# TMS320F280049 register map
Vendor: Texas Instruments; Series: C2000 F28004x; File version: 0.2.0-generated
Registers are 16-bit, read-write, reset 0x0 unless marked. A register's access mark holds for its fields unless they carry their own. Offsets are from the block's base; [hi:lo] are bit positions; {n}, {i} and the like mark numbered series.

## ADCARESULTREGS — ADC RESULT Registers
Base 0x00001600
Same registers: ADCBRESULTREGS 0x00001640, ADCCRESULTREGS 0x00001680
{0x0+2i} ADCRESULT{i} (i=0..15)
  [15] RESULT — ADC Result
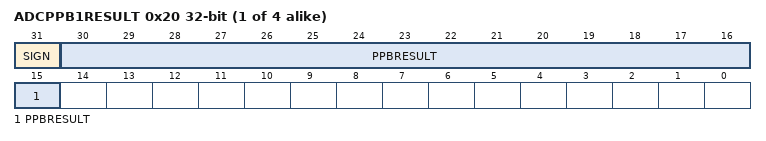
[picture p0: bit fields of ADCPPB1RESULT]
{0x1C+4i} ADCPPB{i}RESULT 32-bit (i=1..4) — ADC Post Processing Block {i} Result Register
  [31] SIGN — Sign Extended Bits
  [30:15] PPBRESULT — ADC Post Processing Block Result

## CLA1ONLYREGS — CLA ONLY Registers
Base 0x00001800
0x100 MVECTBGRNDACTIVE — Active register for MVECTBGRND.
  [15] I16 — Active register for the Background Task Vector
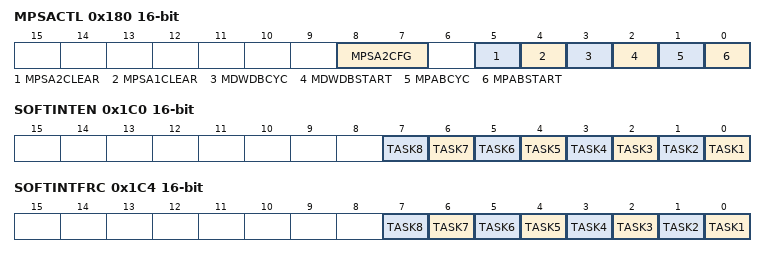
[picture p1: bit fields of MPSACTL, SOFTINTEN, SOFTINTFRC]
0x180 MPSACTL — CLA PSA Control Register
  [8:7] MPSA2CFG — PSA2 Polynomial Configuration
  [5] MPSA2CLEAR — PSA2 Clear
  [4] MPSA1CLEAR — PSA1 clear
  [3] MDWDBCYC — DWDB logging into PSA2 is on every cycle.
  [2] MDWDBSTART — Start logging DWDB onto PSA2
  [1] MPABCYC — PAB logging into PSA1 is on every cycle or when PAB changes.
  [0] MPABSTART — Start logging PAB onto PSA1
0x184 MPSA1 32-bit — CLA PSA1 Register
  [31] I32 — PSA1
0x188 MPSA2 32-bit — CLA PSA2 Register
  [31] I32 — PSA2
0x1C0 SOFTINTEN — CLA Software Interrupt Enable Register
  [n-1] TASK{n} (n=1..8) — Configure Software Interrupt or End of Task interrupt.
0x1C4 SOFTINTFRC — CLA Software Interrupt Force Register
  [n-1] TASK{n} (n=1..8) — Force CLA software interrupt for the corresponding task.

## CPUTIMER0REGS — CPUTIMER Registers
Base 0x00001800
Same registers: CPUTIMER1REGS 0x00001810, CPUTIMER2REGS 0x00001820
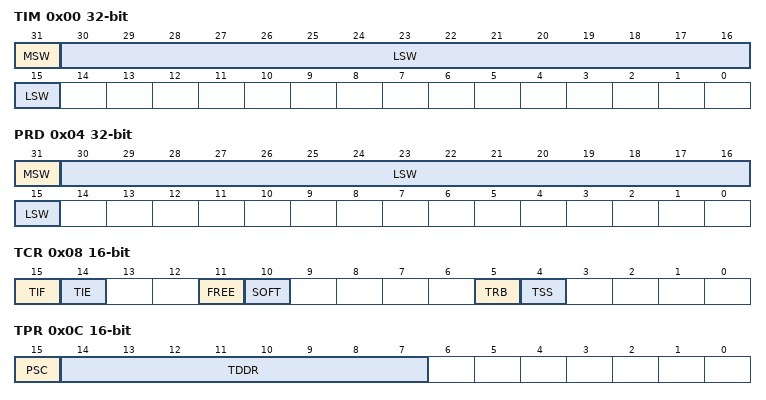
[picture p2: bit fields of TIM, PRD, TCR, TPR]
0x00 TIM 32-bit — CPU-Timer, Counter Register
  [31] MSW — CPU-Timer Counter Registers High
  [30:15] LSW — CPU-Timer Counter Registers
0x04 PRD 32-bit — CPU-Timer, Period Register
  [31] MSW — CPU-Timer Period Registers High
  [30:15] LSW — CPU-Timer Period Registers
0x08 TCR — CPU-Timer, Control Register
  [15] TIF — CPU-Timer Interrupt Flag.
  [14] TIE — CPU-Timer Interrupt Enable.
  [11] FREE — Emulation modes
  [10] SOFT — Emulation modes
  [5] TRB — Timer reload
  [4] TSS — CPU-Timer stop status bit.
0x0C TPR — CPU-Timer, Prescale Register
  [15] PSC — CPU-Timer Prescale Counter.
  [14:7] TDDR — CPU-Timer Divide-Down.
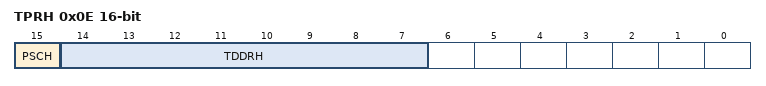
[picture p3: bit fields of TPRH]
0x0E TPRH — CPU-Timer, Prescale Register High
  [15] PSCH — CPU-Timer Prescale Counter.
  [14:7] TDDRH — CPU-Timer Divide-Down.

## FPU — Floating-Point Unit Single Precision Registers
Base 0x00001E00
0x00 RB 32-bit — Repeat Block Register
  [31] RAS — Repeat block shadow active
  [30] RA — Repeat block active
  [31:29] RSIZE — Repeat block size
  [28:22] RE — Repeat block end
  [30:15] RC — Repeat count
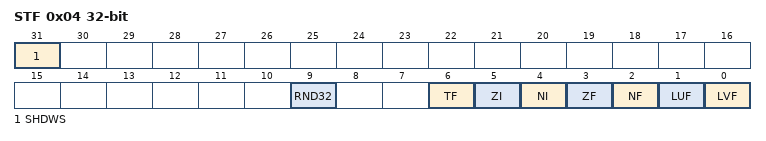
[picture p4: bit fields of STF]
0x04 STF 32-bit — Floating-Point Status Register
  [31] SHDWS — Shadow mode status
  [9] RND32 — Rounding mode
  [6] TF — Test flag
  [5] ZI — Zero integer flag
  [4] NI — Negative integer flag
  [3] ZF — Zero float flag
  [2] NF — Negative flaot flag
  [1] LUF — Latched underflow
  [0] LVF — Latched overflow
{0x24+8i} R{i}H 32-bit (i=0..7)

## DMAREGS — DMA Registers
Base 0x00002000
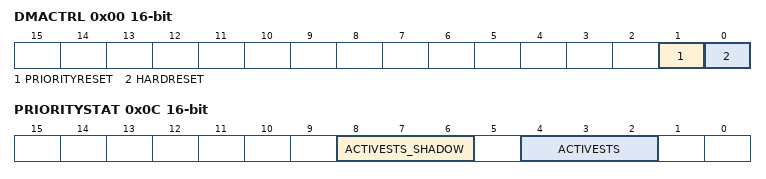
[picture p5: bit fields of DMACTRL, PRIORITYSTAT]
0x00 DMACTRL — DMA Control Register
  [1] PRIORITYRESET — Priority Reset Bit
  [0] HARDRESET — Hard Reset Bit
0x02 DEBUGCTRL — Debug Control Register
  [15] FREE — Debug Mode Bit
0x08 PRIORITYCTRL1 — Priority Control 1 Register
  [0] CH1PRIORITY — Ch1 Priority Bit
0x0C PRIORITYSTAT — Priority Status Register
  [8:6] ACTIVESTS_SHADOW — Active Channel Status Shadow Bits
  [4:2] ACTIVESTS — Active Channel Status Bits

## DMACH1REGS — DMA CH Registers
Base 0x00002040
Same registers: DMACH2REGS 0x00002080, DMACH3REGS 0x000020C0, DMACH4REGS 0x00002100, DMACH5REGS 0x00002140, DMACH6REGS 0x00002180
0x00 MODE
  [15] CHINTE — Channel Interrupt Enable Bit
  [14] DATASIZE — Data Size Mode Bit
  [11] CONTINUOUS — Continuous Mode Bit
  [10] ONESHOT — One Shot Mode Bit
  [9] CHINTMODE — Channel Interrupt Mode
  [8] PERINTE — Peripheral Interrupt Enable
  [7] OVRINTE — Overflow Interrupt Enable
  [8:4] PERINTSEL — Peripheral Interrupt and Sync Select
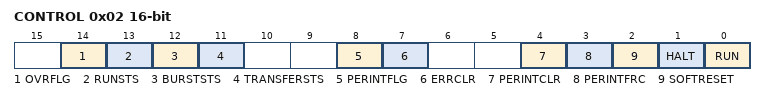
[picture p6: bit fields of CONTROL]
0x02 CONTROL
  [14] OVRFLG — Overflow Flag Bit
  [13] RUNSTS — Run Status Bit
  [12] BURSTSTS — Burst Status Bit
  [11] TRANSFERSTS — Transfer Status Bit
  [8] PERINTFLG — Interrupt Flag Bit
  [7] ERRCLR — Error Clear Bit
  [4] PERINTCLR — Interrupt Clear Bit
  [3] PERINTFRC — Interrupt Force Bit
  [2] SOFTRESET — Soft Reset Bit
  [1] HALT — Halt Bit
  [0] RUN — Run Bit
0x04 BURST_SIZE
  [8:4] BURSTSIZE — Burst Transfer Size
0x06 BURST_COUNT
  [8:4] BURSTCOUNT — Burst Transfer Size
0x08 SRC_BURST_STEP — Source Burst Step Register
  [15] SRCBURSTSTEP — Source post-increment/decrement step size of a burst
0x0A DST_BURST_STEP — Destination Burst Step Register
  [15] DSTBURSTSTEP — Destination post-increment/decrement step size of a burst
0x0C TRANSFER_SIZE
  [15] TRANSFERSIZE — These bits specify the number of bursts to transfer:
0x0E TRANSFER_COUNT
  [15] TRANSFERCOUNT — These bits specify the current transfer counter value:
0x10 SRC_TRANSFER_STEP — Source Transfer Step Register
  [15] SRCTRANSFERSTEP — Source post-increment/decrement step size of a transfer
0x12 DST_TRANSFER_STEP — Destination Transfer Step Register
  [15] DSTTRANSFERSTEP — Destination post-increment/decrement step size of a transfer
0x14 SRC_WRAP_SIZE — Source Wrap Size Register
  [15] WRAPSIZE — Number of bursts to transfer before wrapping
0x16 SRC_WRAP_COUNT — Source Wrap Count Register
  [15] WRAPSIZE — These bits indicate the current wrap counter value:
0x18 SRC_WRAP_STEP — Source Wrap Step Register
  [15] WRAPSTEP — Source post-increment/decrement step size for a wrap
0x1A DST_WRAP_SIZE — Destination Wrap Size Register
  [15] WRAPSIZE — Number of bursts to transfer before wrapping
0x1C DST_WRAP_COUNT — Destination Wrap Count Register
  [15] WRAPSIZE — These bits indicate the current wrap counter value:
0x1E DST_WRAP_STEP — Destination Wrap Step Register
  [15] WRAPSTEP — Destination post-increment/decrement step size for a wrap
0x20 SRC_BEG_ADDR_SHADOW 32-bit — Source Begin Address Shadow Register
  [31] BEGADDR — 32-bit address value
0x24 SRC_ADDR_SHADOW 32-bit — Source Address Shadow Register
  [31] ADDR — 32-bit address value
0x28 SRC_BEG_ADDR_ACTIVE 32-bit — Source Begin Address Active Register
  [31] BEGADDR — 32-bit address value
0x2C SRC_ADDR_ACTIVE 32-bit — Source Address Active Register
  [31] ADDR — 32-bit address value
0x30 DST_BEG_ADDR_SHADOW 32-bit — Destination Begin Address Shadow Register
  [31] BEGADDR — 32-bit address value
0x34 DST_ADDR_SHADOW 32-bit — Destination Address Shadow Register
  [31] ADDR — 32-bit address value
0x38 DST_BEG_ADDR_ACTIVE 32-bit — Destination Begin Address Active Register
  [31] BEGADDR — 32-bit address value
0x3C DST_ADDR_ACTIVE 32-bit — Destination Address Active Register
  [31] ADDR — 32-bit address value
